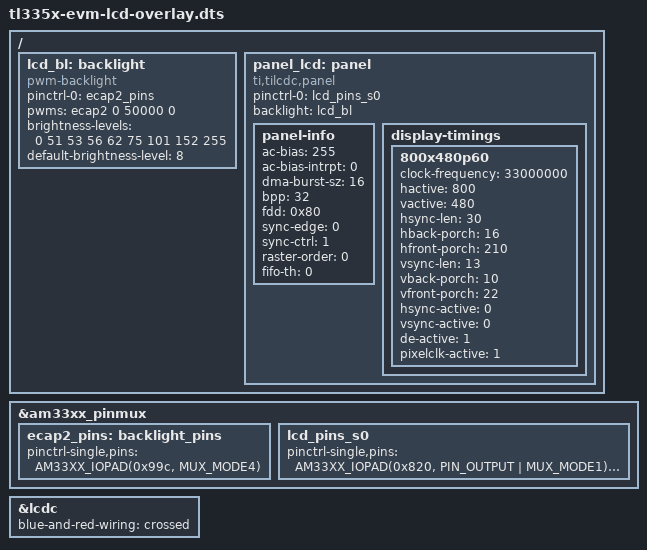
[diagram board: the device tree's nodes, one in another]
/*
 * Copyright (C) 2015 GuangZhou Tronlong co., LTD - http://www.tronlong.com
 *
 * This program is free software; you can redistribute it and/or modify
 * it under the terms of the GNU General Public License version 2 as
 * published by the Free Software Foundation.
 */

/* device tree overlay for TL335x-EVM board with 7-inch lcd */

/dts-v1/;
/plugin/;

#include <dt-bindings/interrupt-controller/irq.h>
#include <dt-bindings/input/input.h>
#include <dt-bindings/gpio/gpio.h>
#include <dt-bindings/pinctrl/am33xx.h>

/ {
	fragment@0 {
		target = <&am33xx_pinmux>;
		__overlay__ {
			ecap2_pins: backlight_pins {
				pinctrl-single,pins = <
					AM33XX_IOPAD(0x99c, MUX_MODE4)	/* MCASP0_AHCLKR.ECAP2_IN_PWM2_OUT */
				>;
			};

			lcd_pins_s0: lcd_pins_s0 {
				pinctrl-single,pins = <
					AM33XX_IOPAD(0x820, PIN_OUTPUT | MUX_MODE1)		/* gpmc_ad8.lcd_data23 */
					AM33XX_IOPAD(0x824, PIN_OUTPUT | MUX_MODE1)		/* gpmc_ad9.lcd_data22 */
					AM33XX_IOPAD(0x828, PIN_OUTPUT | MUX_MODE1)		/* gpmc_ad10.lcd_data21 */
					AM33XX_IOPAD(0x82c, PIN_OUTPUT | MUX_MODE1)		/* gpmc_ad11.lcd_data20 */
					AM33XX_IOPAD(0x830, PIN_OUTPUT | MUX_MODE1)		/* gpmc_ad12.lcd_data19 */
					AM33XX_IOPAD(0x834, PIN_OUTPUT | MUX_MODE1)		/* gpmc_ad13.lcd_data18 */
					AM33XX_IOPAD(0x838, PIN_OUTPUT | MUX_MODE1)		/* gpmc_ad14.lcd_data17 */
					AM33XX_IOPAD(0x83c, PIN_OUTPUT | MUX_MODE1)		/* gpmc_ad15.lcd_data16 */
					AM33XX_IOPAD(0x8a0, PIN_OUTPUT | MUX_MODE0)		/* lcd_data0.lcd_data0 */
					AM33XX_IOPAD(0x8a4, PIN_OUTPUT | MUX_MODE0)		/* lcd_data1.lcd_data1 */
					AM33XX_IOPAD(0x8a8, PIN_OUTPUT | MUX_MODE0)		/* lcd_data2.lcd_data2 */
					AM33XX_IOPAD(0x8ac, PIN_OUTPUT | MUX_MODE0)		/* lcd_data3.lcd_data3 */
					AM33XX_IOPAD(0x8b0, PIN_OUTPUT | MUX_MODE0)		/* lcd_data4.lcd_data4 */
					AM33XX_IOPAD(0x8b4, PIN_OUTPUT | MUX_MODE0)		/* lcd_data5.lcd_data5 */
					AM33XX_IOPAD(0x8b8, PIN_OUTPUT | MUX_MODE0)		/* lcd_data6.lcd_data6 */
					AM33XX_IOPAD(0x8bc, PIN_OUTPUT | MUX_MODE0)		/* lcd_data7.lcd_data7 */
					AM33XX_IOPAD(0x8c0, PIN_OUTPUT | MUX_MODE0)		/* lcd_data8.lcd_data8 */
					AM33XX_IOPAD(0x8c4, PIN_OUTPUT | MUX_MODE0)		/* lcd_data9.lcd_data9 */
					AM33XX_IOPAD(0x8c8, PIN_OUTPUT | MUX_MODE0)		/* lcd_data10.lcd_data10 */
					AM33XX_IOPAD(0x8cc, PIN_OUTPUT | MUX_MODE0)		/* lcd_data11.lcd_data11 */
					AM33XX_IOPAD(0x8d0, PIN_OUTPUT | MUX_MODE0)		/* lcd_data12.lcd_data12 */
					AM33XX_IOPAD(0x8d4, PIN_OUTPUT | MUX_MODE0)		/* lcd_data13.lcd_data13 */
					AM33XX_IOPAD(0x8d8, PIN_OUTPUT | MUX_MODE0)		/* lcd_data14.lcd_data14 */
					AM33XX_IOPAD(0x8dc, PIN_OUTPUT | MUX_MODE0)		/* lcd_data15.lcd_data15 */
					AM33XX_IOPAD(0x8e0, PIN_OUTPUT | MUX_MODE0)		/* lcd_vsync.lcd_vsync */
					AM33XX_IOPAD(0x8e4, PIN_OUTPUT | MUX_MODE0)		/* lcd_hsync.lcd_hsync */
					AM33XX_IOPAD(0x8e8, PIN_OUTPUT | MUX_MODE0)		/* lcd_pclk.lcd_pclk */
					AM33XX_IOPAD(0x8ec, PIN_OUTPUT | MUX_MODE0)		/* lcd_ac_bias_en.lcd_ac_bias_en */
				>;
			};
		};
	};

	fragment@1 {
		target-path = "/";
		__overlay__ {
			lcd_bl: backlight {
				compatible = "pwm-backlight";
				pinctrl-names = "default";
				pinctrl-0 = <&ecap2_pins>;
				pwms = <&ecap2 0 50000 0>;
				brightness-levels = <0 51 53 56 62 75 101 152 255>;
				default-brightness-level = <8>;
			};

			panel_lcd: panel {
				compatible = "ti,tilcdc,panel";
				status = "okay";
				pinctrl-names = "default";
				pinctrl-0 = <&lcd_pins_s0>;
				backlight = <&lcd_bl>;

				panel-info {
					ac-bias           = <255>;
					ac-bias-intrpt    = <0>;
					dma-burst-sz      = <16>;
					bpp               = <32>;
					fdd               = <0x80>;
					sync-edge         = <0>;
					sync-ctrl         = <1>;
					raster-order      = <0>;
					fifo-th           = <0>;
				};

				display-timings {
					800x480p60 {
						clock-frequency = <33000000>;
						hactive = <800>;
						vactive = <480>;

						hsync-len = <30>;
						hback-porch = <16>;
						hfront-porch = <210>;

						vsync-len = <13>;
						vback-porch = <10>;
						vfront-porch = <22>;

						hsync-active = <0>;
						vsync-active = <0>;
						de-active = <1>;
						pixelclk-active = <1>;
					};
				};
			};
		};
	};

	fragment@2 {
		target = <&lcdc>;
		__overlay__ {
			status = "okay";
			blue-and-red-wiring = "crossed";
		};
	};
};
